# bao1x register map
Vendor: baochip; File version: 1.0
Registers are 32-bit, read-write, reset 0x0 unless marked. A register's access mark holds for its fields unless they carry their own. Offsets are from the block's base; [hi:lo] are bit positions; <NAME> marks a mode.

## AO_SYSCTRL
Base 0x40060000
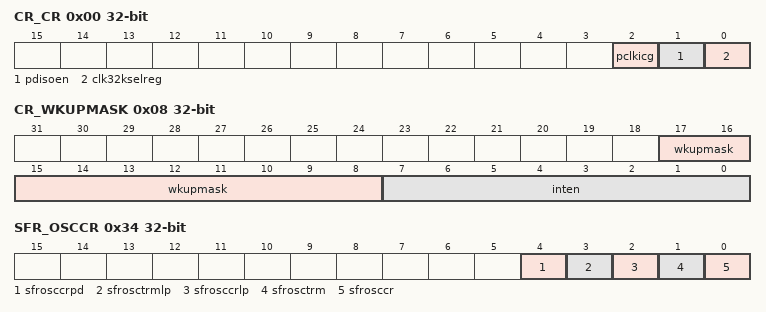
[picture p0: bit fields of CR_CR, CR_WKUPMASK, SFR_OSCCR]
0x00 CR_CR — See `ao_sysctrl.sv#L367 <https://github.com/baochip/baochip-1x/blob/main/rtl/mod ules/ao/rtl/ao_sysctrl.sv#L367>`__ (line numbers are approximate)
  [2] pclkicg — pclkicg read/write control register
  [1] pdisoen — pdisoen read/write control register
  [0] clk32kselreg — clk32kselreg read/write control register
0x04 CR_CLK1HZFD — See `ao_sysctrl.sv#L368 <https://github.com/baochip/baochip-1x/blob/main/rtl/mod ules/ao/rtl/ao_sysctrl.sv#L368>`__ (line numbers are approximate)
  [13:0] cr_clk1hzfd — cr_clk1hzfd read/write control register
0x08 CR_WKUPMASK — See `ao_sysctrl.sv#L369 <https://github.com/baochip/baochip-1x/blob/main/rtl/mod ules/ao/rtl/ao_sysctrl.sv#L369>`__ (line numbers are approximate)
  [17:8] wkupmask — wkupmask read/write control register
  [7:0] inten — inten read/write control register
0x0C CR_RSTCRMASK — See `ao_sysctrl.sv#L370 <https://github.com/baochip/baochip-1x/blob/main/rtl/mod ules/ao/rtl/ao_sysctrl.sv#L370>`__ (line numbers are approximate)
  [4:0] cr_rstcrmask — cr_rstcrmask read/write control register
0x10 SFR_PMUCSR — See `ao_sysctrl.sv#L376 <https://github.com/baochip/baochip-1x/blob/main/rtl/mod ules/ao/rtl/ao_sysctrl.sv#L376>`__ (line numbers are approximate)
  [7:0] pmucrreg — pmucrreg read only status register
0x14 SFR_PMUCRLP — See `ao_sysctrl.sv#L373 <https://github.com/baochip/baochip-1x/blob/main/rtl/mod ules/ao/rtl/ao_sysctrl.sv#L373>`__ (line numbers are approximate)
  [7:0] sfrpmucrlp — sfrpmucrlp read/write control register
0x18 SFR_PMUCRPD — See `ao_sysctrl.sv#L374 <https://github.com/baochip/baochip-1x/blob/main/rtl/mod ules/ao/rtl/ao_sysctrl.sv#L374>`__ (line numbers are approximate)
  [7:0] sfrpmucrpd — sfrpmucrpd read/write control register
0x1C SFR_PMUDFTSR — See `ao_sysctrl.sv#L377 <https://github.com/baochip/baochip-1x/blob/main/rtl/mod ules/ao/rtl/ao_sysctrl.sv#L377>`__ (line numbers are approximate)
  [5:0] pmudftreg — pmudftreg read only status register
0x20 SFR_PMUTRM0CSR — See `ao_sysctrl.sv#L383 <https://github.com/baochip/baochip-1x/blob/main/rtl/mod ules/ao/rtl/ao_sysctrl.sv#L383>`__ (line numbers are approximate)
  [31:0] pmutrmreg — pmutrmreg read only status register
0x24 SFR_PMUTRM1CSR — See `ao_sysctrl.sv#L384 <https://github.com/baochip/baochip-1x/blob/main/rtl/mod ules/ao/rtl/ao_sysctrl.sv#L384>`__ (line numbers are approximate)
  [1:0] pmutrmreg — pmutrmreg read only status register
0x28 SFR_PMUTRMLP0 — See `ao_sysctrl.sv#L381 <https://github.com/baochip/baochip-1x/blob/main/rtl/mod ules/ao/rtl/ao_sysctrl.sv#L381>`__ (line numbers are approximate)
  [31:0] sfrpmutrmlp — sfrpmutrmlp read/write control register
0x2C SFR_PMUTRMLP1 — See `ao_sysctrl.sv#L382 <https://github.com/baochip/baochip-1x/blob/main/rtl/mod ules/ao/rtl/ao_sysctrl.sv#L382>`__ (line numbers are approximate)
  [1:0] sfrpmutrmlp — sfrpmutrmlp read/write control register
0x34 SFR_OSCCR — See `ao_sysctrl.sv#L386 <https://github.com/baochip/baochip-1x/blob/main/rtl/mod ules/ao/rtl/ao_sysctrl.sv#L386>`__ (line numbers are approximate)
  [4] sfrosccrpd — sfrosccrpd read/write control register
  [3] sfrosctrmlp — sfrosctrmlp read/write control register
  [2] sfrosccrlp — sfrosccrlp read/write control register
  [1] sfrosctrm — sfrosctrm read/write control register
  [0] sfrosccr — sfrosccr read/write control register
0x38 SFR_PMUSR — See `ao_sysctrl.sv#L387 <https://github.com/baochip/baochip-1x/blob/main/rtl/mod ules/ao/rtl/ao_sysctrl.sv#L387>`__ (line numbers are approximate)
  [4:0] sfr_pmusr — sfr_pmusr read only status register
0x3C SFR_PMUFR — See `ao_sysctrl.sv#L388 <https://github.com/baochip/baochip-1x/blob/main/rtl/mod ules/ao/rtl/ao_sysctrl.sv#L388>`__ (line numbers are approximate)
  [4:0] sfr_pmufr — sfr_pmufr flag register. `1` means event happened, write back `1` in respective bit position to clear the flag
0x40 SFR_AOFR — See `ao_sysctrl.sv#L390 <https://github.com/baochip/baochip-1x/blob/main/rtl/mod ules/ao/rtl/ao_sysctrl.sv#L390>`__ (line numbers are approximate)
  [9:0] sfr_aofr — sfr_aofr flag register. `1` means event happened, write back `1` in respective bit position to clear the flag
0x44 SFR_PMUPDAR — See `ao_sysctrl.sv#L391 <https://github.com/baochip/baochip-1x/blob/main/rtl/mod ules/ao/rtl/ao_sysctrl.sv#L391>`__ (line numbers are approximate)
  [31:0] sfr_pmupdar — sfr_pmupdar performs action on write of value: 0x5a
0x50 AR_AOPERI_CLRINT — See `ao_sysctrl.sv#L393 <https://github.com/baochip/baochip-1x/blob/main/rtl/mod ules/ao/rtl/ao_sysctrl.sv#L393>`__ (line numbers are approximate)
  [31:0] ar_aoperi_clrint — ar_aoperi_clrint performs action on write of value: 0xaa
0x60 SFR_IOX — See `ao_sysctrl.sv#L400 <https://github.com/baochip/baochip-1x/blob/main/rtl/mod ules/ao/rtl/ao_sysctrl.sv#L400>`__ (line numbers are approximate)
  [0] sfr_iox — sfr_iox read/write control register
0x64 SFR_AOPADPU — See `ao_sysctrl.sv#L401 <https://github.com/baochip/baochip-1x/blob/main/rtl/mod ules/ao/rtl/ao_sysctrl.sv#L401>`__ (line numbers are approximate)
  [9:0] sfr_aopadpu — sfr_aopadpu read/write control register
